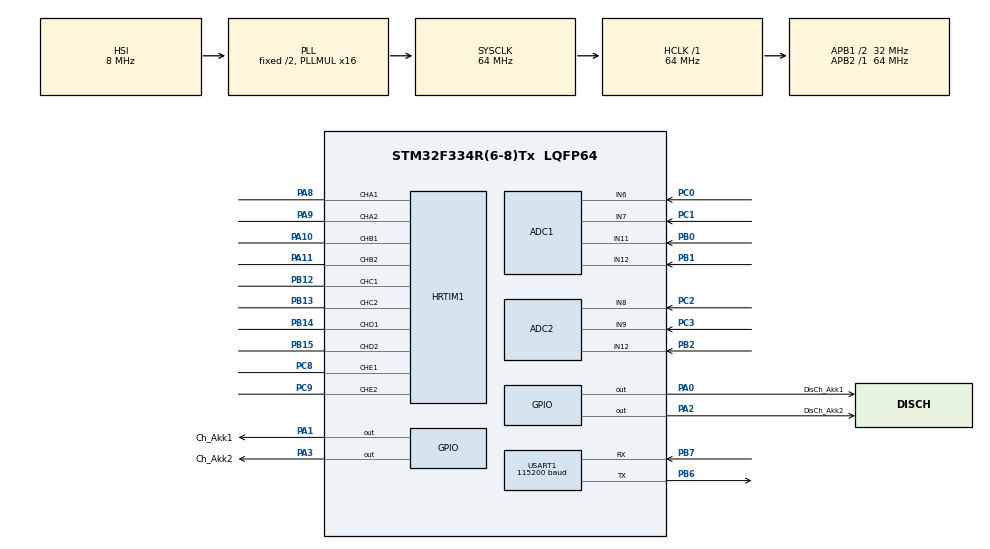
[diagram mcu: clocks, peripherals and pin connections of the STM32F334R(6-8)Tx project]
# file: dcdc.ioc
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ADC1.Channel-0\#ChannelRegularConversion=ADC_CHANNEL_6
ADC1.Channel-1\#ChannelRegularConversion=ADC_CHANNEL_7
ADC1.Channel-2\#ChannelRegularConversion=ADC_CHANNEL_11
ADC1.Channel-3\#ChannelRegularConversion=ADC_CHANNEL_12
ADC1.DMAContinuousRequests=ENABLE
ADC1.DiscontinuousConvMode=ENABLE
ADC1.EOCSelection=ADC_EOC_SINGLE_CONV
ADC1.EnableInjectedConversion=DISABLE
ADC1.ExternalTrigConv=ADC_EXTERNALTRIGCONV_T15_TRGO
ADC1.NbrOfConversion=4
ADC1.NbrOfConversionFlag=1
ADC1.Offset-0\#ChannelRegularConversion=0
ADC1.Offset-1\#ChannelRegularConversion=0
ADC1.Offset-2\#ChannelRegularConversion=0
ADC1.Offset-3\#ChannelRegularConversion=0
ADC1.OffsetNumber-0\#ChannelRegularConversion=ADC_OFFSET_NONE
ADC1.OffsetNumber-1\#ChannelRegularConversion=ADC_OFFSET_NONE
ADC1.OffsetNumber-2\#ChannelRegularConversion=ADC_OFFSET_NONE
ADC1.OffsetNumber-3\#ChannelRegularConversion=ADC_OFFSET_NONE
ADC1.Rank-0\#ChannelRegularConversion=1
ADC1.Rank-1\#ChannelRegularConversion=2
ADC1.Rank-2\#ChannelRegularConversion=3
ADC1.Rank-3\#ChannelRegularConversion=4
ADC1.SamplingTime-0\#ChannelRegularConversion=ADC_SAMPLETIME_1CYCLE_5
ADC1.SamplingTime-1\#ChannelRegularConversion=ADC_SAMPLETIME_1CYCLE_5
ADC1.SamplingTime-2\#ChannelRegularConversion=ADC_SAMPLETIME_1CYCLE_5
ADC1.SamplingTime-3\#ChannelRegularConversion=ADC_SAMPLETIME_1CYCLE_5
ADC1.SamplingTimeOPAMP-1\#ChannelRegularConversion=ADC_SAMPLETIME_61CYCLES_5
ADC1.SamplingTimeOPAMP-2\#ChannelRegularConversion=ADC_SAMPLETIME_61CYCLES_5
ADC1.SamplingTimeOPAMP-3\#ChannelRegularConversion=ADC_SAMPLETIME_61CYCLES_5
ADC1.SubFamily=STM32F334x8
ADC1.master=1
ADC2.Channel-0\#ChannelRegularConversion=ADC_CHANNEL_8
ADC2.Channel-1\#ChannelRegularConversion=ADC_CHANNEL_9
ADC2.Channel-2\#ChannelRegularConversion=ADC_CHANNEL_12
ADC2.DMAContinuousRequests=ENABLE
ADC2.DiscontinuousConvMode=DISABLE
ADC2.EnableInjectedConversion=DISABLE
ADC2.ExternalTrigConv=ADC_EXTERNALTRIGCONV_T15_TRGO
ADC2.NbrOfConversion=3
ADC2.NbrOfConversionFlag=1
ADC2.Offset-0\#ChannelRegularConversion=0
ADC2.Offset-1\#ChannelRegularConversion=0
ADC2.Offset-2\#ChannelRegularConversion=0
ADC2.OffsetNumber-0\#ChannelRegularConversion=ADC_OFFSET_NONE
ADC2.OffsetNumber-1\#ChannelRegularConversion=ADC_OFFSET_NONE
ADC2.OffsetNumber-2\#ChannelRegularConversion=ADC_OFFSET_NONE
ADC2.Rank-0\#ChannelRegularConversion=1
ADC2.Rank-1\#ChannelRegularConversion=2
ADC2.Rank-2\#ChannelRegularConversion=3
ADC2.SamplingTime-0\#ChannelRegularConversion=ADC_SAMPLETIME_61CYCLES_5
ADC2.SamplingTime-1\#ChannelRegularConversion=ADC_SAMPLETIME_61CYCLES_5
ADC2.SamplingTime-2\#ChannelRegularConversion=ADC_SAMPLETIME_61CYCLES_5
ADC2.SamplingTimeOPAMP-1\#ChannelRegularConversion=ADC_SAMPLETIME_61CYCLES_5
ADC2.SamplingTimeOPAMP-2\#ChannelRegularConversion=ADC_SAMPLETIME_61CYCLES_5
ADC2.SubFamily=STM32F334x8
Dma.ADC1.2.Direction=DMA_PERIPH_TO_MEMORY
Dma.ADC1.2.Instance=DMA1_Channel1
Dma.ADC1.2.MemDataAlignment=DMA_MDATAALIGN_HALFWORD
Dma.ADC1.2.MemInc=DMA_MINC_ENABLE
Dma.ADC1.2.Mode=DMA_CIRCULAR
Dma.ADC1.2.PeriphDataAlignment=DMA_PDATAALIGN_HALFWORD
Dma.ADC1.2.PeriphInc=DMA_PINC_DISABLE
Dma.ADC1.2.Priority=DMA_PRIORITY_LOW
Dma.ADC2.3.Direction=DMA_PERIPH_TO_MEMORY
Dma.ADC2.3.Instance=DMA1_Channel2
Dma.ADC2.3.MemDataAlignment=DMA_MDATAALIGN_HALFWORD
Dma.ADC2.3.MemInc=DMA_MINC_ENABLE
Dma.ADC2.3.Mode=DMA_CIRCULAR
Dma.ADC2.3.PeriphDataAlignment=DMA_PDATAALIGN_HALFWORD
Dma.ADC2.3.PeriphInc=DMA_PINC_DISABLE
Dma.ADC2.3.Priority=DMA_PRIORITY_LOW
Dma.Request0=USART1_RX
Dma.Request1=USART1_TX
Dma.Request2=ADC1
Dma.Request3=ADC2
Dma.USART1_RX.0.Direction=DMA_PERIPH_TO_MEMORY
Dma.USART1_RX.0.Instance=DMA1_Channel5
Dma.USART1_RX.0.MemDataAlignment=DMA_MDATAALIGN_BYTE
Dma.USART1_RX.0.MemInc=DMA_MINC_ENABLE
Dma.USART1_RX.0.Mode=DMA_NORMAL
Dma.USART1_RX.0.PeriphDataAlignment=DMA_PDATAALIGN_BYTE
Dma.USART1_RX.0.PeriphInc=DMA_PINC_DISABLE
Dma.USART1_RX.0.Priority=DMA_PRIORITY_LOW
Dma.USART1_TX.1.Direction=DMA_MEMORY_TO_PERIPH
Dma.USART1_TX.1.Instance=DMA1_Channel4
Dma.USART1_TX.1.MemDataAlignment=DMA_MDATAALIGN_BYTE
Dma.USART1_TX.1.MemInc=DMA_MINC_ENABLE
Dma.USART1_TX.1.Mode=DMA_NORMAL
Dma.USART1_TX.1.PeriphDataAlignment=DMA_PDATAALIGN_BYTE
Dma.USART1_TX.1.PeriphInc=DMA_PINC_DISABLE
Dma.USART1_TX.1.Priority=DMA_PRIORITY_LOW
FREERTOS.INCLUDE_xEventGroupSetBitFromISR=1
FREERTOS.INCLUDE_xTimerPendFunctionCall=1
FREERTOS.Queues01=command_queue,100,uint8_t,0,Dynamic,NULL,NULL
FREERTOS.Tasks01=defaultTask,0,128,StartDefaultTask,Default,NULL,Dynamic,NULL,NULL;rx_uart_data,0,128,rx_uart_data_task,As weak,NULL,Dynamic,NULL,NULL;tx_uart_data,0,128,tx_uart_data_task,As weak,NULL,Dynamic,NULL,NULL;charging_akk,2,128,charging_akk_task,As weak,NULL,Dynamic,NULL,NULL
FREERTOS.configLIBRARY_LOWEST_INTERRUPT_PRIORITY=3
FREERTOS.configLIBRARY_MAX_SYSCALL_INTERRUPT_PRIORITY=3
FREERTOS.configUSE_TIMERS=1
HRTIM1.ADCTrigger_Id3=__NULL
HRTIM1.CaptureUnit1-Output_TB1TB2=__NULL
HRTIM1.CompareUnit1-MasterTimer=__NULL
HRTIM1.CompareUnit1-Output_TA1TA2=__NULL
HRTIM1.CompareUnit1-Output_TB1TB2=__NULL
HRTIM1.CompareUnit1-Output_TC1TC2=__NULL
HRTIM1.CompareUnit1-Output_TD1TD2=__NULL
HRTIM1.CompareUnit2-MasterTimer=HRTIM_COMPAREUNIT_2
HRTIM1.CompareUnit2-Output_TA1TA2=__NULL
HRTIM1.CompareUnit2-Output_TB1TB2=__NULL
HRTIM1.CompareUnit2-Output_TC1TC2=__NULL
HRTIM1.CompareUnit2-Output_TD1TD2=__NULL
HRTIM1.CompareUnit3-MasterTimer=HRTIM_COMPAREUNIT_3
HRTIM1.CompareUnit3-Output_TA1TA2=__NULL
HRTIM1.CompareUnit3-Output_TB1TB2=__NULL
HRTIM1.CompareUnit3-Output_TC1TC2=__NULL
HRTIM1.CompareUnit3-Output_TD1TD2=__NULL
HRTIM1.CompareUnit4-MasterTimer=HRTIM_COMPAREUNIT_4
HRTIM1.CompareUnit4-Output_TA1TA2=__NULL
HRTIM1.CompareUnit4-Output_TB1TB2=__NULL
HRTIM1.CompareUnit4-Output_TC1TC2=__NULL
HRTIM1.CompareUnit4-Output_TD1TD2=__NULL
HRTIM1.CompareValue1-MasterTimer=160
HRTIM1.CompareValue1-Output_TA1TA2=3
HRTIM1.CompareValue1-Output_TB1TB2=3
HRTIM1.CompareValue1-Output_TC1TC2=3
HRTIM1.CompareValue1-Output_TD1TD2=3
HRTIM1.CompareValue2-MasterTimer=80
HRTIM1.CompareValue2-Output_TA1TA2=323
HRTIM1.CompareValue2-Output_TB1TB2=323
HRTIM1.CompareValue2-Output_TC1TC2=323
HRTIM1.CompareValue2-Output_TD1TD2=323
HRTIM1.CompareValue3-MasterTimer=160
HRTIM1.CompareValue3-Output_TB1TB2=65533
HRTIM1.CompareValue4-MasterTimer=240
HRTIM1.CompareValue4-Output_TB1TB2=65533
HRTIM1.Configuration_TE=Waveform
HRTIM1.Deadtimeconfig-Output_TB1TB2=__NULL
HRTIM1.Event2-Output_TA1TA2=__NULL
HRTIM1.Event_EEV1=__NULL
HRTIM1.Event_EEV2=__NULL
HRTIM1.Event_EEV5=__NULL
HRTIM1.Event_EEV6=__NULL
HRTIM1.Event_EEV7=__NULL
HRTIM1.Fault_Line1=__NULL
HRTIM1.Fault_Line2=__NULL
HRTIM1.HalfModeEnable-MasterTimer=HRTIM_HALFMODE_DISABLED
HRTIM1.InterruptRequests1_Master=HRTIM_MASTER_IT_NONE
HRTIM1.InterruptRequests2_Master=HRTIM_MASTER_IT_MCMP2
HRTIM1.InterruptRequests3_Master=HRTIM_MASTER_IT_MCMP3
HRTIM1.InterruptRequests4_Master=HRTIM_MASTER_IT_MCMP4
HRTIM1.NumberInterruptRequests-Output_TA1TA2=0
HRTIM1.NumberInterruptRequests_Master-MasterTimer=4
HRTIM1.NumberResetSource1-Output_TA1TA2=1
HRTIM1.NumberResetSource1-Output_TB1TB2=1
HRTIM1.NumberResetSource1-Output_TC1TC2=1
HRTIM1.NumberResetSource1-Output_TD1TD2=1
HRTIM1.NumberResetSource1-Output_TE1TE2=1
HRTIM1.NumberResetSource2_TA=1
HRTIM1.NumberResetSource2_TB=1
HRTIM1.NumberResetSource2_TC=1
HRTIM1.NumberResetSource2_TD=1
HRTIM1.NumberResetTrigger-Output_TA1TA2=0
HRTIM1.NumberSetSource1-Output_TA1TA2=1
HRTIM1.NumberSetSource1-Output_TB1TB2=1
HRTIM1.NumberSetSource1-Output_TC1TC2=1
HRTIM1.NumberSetSource1-Output_TD1TD2=1
HRTIM1.NumberSetSource1-Output_TE1TE2=1
HRTIM1.NumberSetSource2_TA=1
HRTIM1.NumberSetSource2_TB=1
HRTIM1.NumberSetSource2_TC=1
HRTIM1.NumberSetSource2_TD=1
HRTIM1.NumberTriggerSource_Captureconfig1-Output_TB1TB2=0
HRTIM1.OCChannel_TE2=__NULL
HRTIM1.ORingUpdateSource_ADCTrigger3=HRTIM_ADCTRIGGERUPDATE_TIMER_A
HRTIM1.PWMChannel_TE1=__NULL
HRTIM1.Periode_MASTER=320
HRTIM1.Periode_TA=640
HRTIM1.Periode_TB=640
HRTIM1.Periode_TE=640
HRTIM1.Polarity1-Output_TB1TB2=HRTIM_OUTPUTPOLARITY_HIGH
HRTIM1.PrescalerRatio_MASTER=HRTIM_PRESCALERRATIO_DIV1
HRTIM1.ResetOutput1_Source1-Output_TA1TA2=HRTIM_OUTPUTRESET_MASTERCMP4
HRTIM1.ResetOutput1_Source1-Output_TB1TB2=HRTIM_OUTPUTRESET_MASTERCMP2
HRTIM1.ResetOutput1_Source1-Output_TC1TC2=HRTIM_OUTPUTRESET_MASTERCMP4
HRTIM1.ResetOutput1_Source1-Output_TD1TD2=HRTIM_OUTPUTRESET_MASTERCMP4
HRTIM1.ResetOutput1_Source1-Output_TE1TE2=HRTIM_OUTPUTRESET_MASTERCMP2
HRTIM1.ResetOutput2_Source1-Output_TA1TA2=HRTIM_OUTPUTRESET_MASTERCMP2
HRTIM1.ResetOutput2_Source1-Output_TB1TB2=HRTIM_OUTPUTRESET_MASTERCMP4
HRTIM1.ResetOutput2_Source1-Output_TC1TC2=HRTIM_OUTPUTRESET_MASTERCMP2
HRTIM1.ResetOutput2_Source1-Output_TD1TD2=HRTIM_OUTPUTRESET_MASTERCMP2
HRTIM1.SetOutput1_Source1-Output_TA1TA2=HRTIM_OUTPUTSET_MASTERCMP3
HRTIM1.SetOutput1_Source1-Output_TB1TB2=HRTIM_OUTPUTSET_MASTERPER
HRTIM1.SetOutput1_Source1-Output_TC1TC2=HRTIM_OUTPUTSET_MASTERCMP3
HRTIM1.SetOutput1_Source1-Output_TD1TD2=HRTIM_OUTPUTSET_MASTERCMP3
HRTIM1.SetOutput1_Source1-Output_TE1TE2=HRTIM_OUTPUTSET_NONE
HRTIM1.SetOutput2_Source1-Output_TA1TA2=HRTIM_OUTPUTSET_MASTERPER
HRTIM1.SetOutput2_Source1-Output_TB1TB2=HRTIM_OUTPUTSET_MASTERCMP3
HRTIM1.SetOutput2_Source1-Output_TC1TC2=HRTIM_OUTPUTSET_MASTERPER
HRTIM1.SetOutput2_Source1-Output_TD1TD2=HRTIM_OUTPUTSET_MASTERPER
HRTIM1.SyncOptions=HRTIM_SYNCOPTION_NONE
HRTIM1.TriggerCapture1_Source1-Output_TB1TB2=HRTIM_CAPTURETRIGGER_TIMERB_CMP1
Mcu.Family=STM32F3
Mcu.Name=STM32F334R(6-8)Tx
Mcu.Package=LQFP64
NVIC.ADC1_2_IRQn=true\:3\:0\:true\:false\:true\:false\:true\:true
NVIC.DMA1_Channel1_IRQn=true\:3\:0\:false\:false\:true\:true\:false\:true
NVIC.DMA1_Channel2_IRQn=true\:3\:0\:false\:false\:true\:true\:false\:true
NVIC.DMA1_Channel4_IRQn=true\:3\:0\:false\:false\:true\:true\:false\:true
NVIC.DMA1_Channel5_IRQn=true\:3\:0\:false\:false\:true\:true\:false\:true
NVIC.PriorityGroup=NVIC_PRIORITYGROUP_4
NVIC.TIM1_UP_TIM16_IRQn=true\:0\:0\:false\:false\:true\:false\:false\:true
NVIC.TimeBase=TIM1_UP_TIM16_IRQn
NVIC.TimeBaseIP=TIM1
NVIC.USART1_IRQn=true\:5\:0\:true\:false\:true\:true\:true\:true
PA0.GPIO_Label=DisCh_Akk1
PA0.Signal=GPIO_Output
PA1.GPIO_Label=Ch_Akk1
PA1.Signal=GPIO_Output
PA10.Mode=Output_TB1TB2
PA10.Signal=HRTIM1_CHB1
PA11.Mode=Output_TB1TB2
PA11.Signal=HRTIM1_CHB2
PA13.GPIO_Label=TMS
PA13.Mode=Serial_Wire
PA13.Signal=SYS_JTMS-SWDIO
PA14.GPIO_Label=TCK
PA14.Mode=Serial_Wire
PA14.Signal=SYS_JTCK-SWCLK
PA2.GPIO_Label=DisCh_Akk2
PA2.Signal=GPIO_Output
PA3.GPIO_Label=Ch_Akk2
PA3.Signal=GPIO_Output
PA8.Mode=Output_TA1TA2
PA8.Signal=HRTIM1_CHA1
PA9.Mode=Output_TA1TA2
PA9.Signal=HRTIM1_CHA2
PB0.Mode=IN11-Single-Ended
PB0.Signal=ADC1_IN11
PB1.Mode=IN12-Single-Ended
PB1.Signal=ADC1_IN12
PB12.Mode=Output_TC1TC2
PB12.Signal=HRTIM1_CHC1
PB13.Mode=Output_TC1TC2
PB13.Signal=HRTIM1_CHC2
PB14.Mode=Output_TD1TD2
PB14.Signal=HRTIM1_CHD1
PB15.Mode=Output_TD1TD2
PB15.Signal=HRTIM1_CHD2
PB2.Mode=IN12-Single-Ended
PB2.Signal=ADC2_IN12
PB3.GPIO_Label=SWO
PB3.Signal=SYS_JTDO-TRACESWO
PB6.Mode=Asynchronous
PB6.Signal=USART1_TX
PB7.Mode=Asynchronous
PB7.Signal=USART1_RX
PC0.Signal=ADCx_IN6
PC1.Signal=ADCx_IN7
PC14\ /\ OSC32_IN.Mode=LSE-External-Oscillator
PC14\ /\ OSC32_IN.Signal=RCC_OSC32_IN
PC15\ /\ OSC32_OUT.GPIO_Label=RCC_OSC32_OUT
PC15\ /\ OSC32_OUT.Mode=LSE-External-Oscillator
PC15\ /\ OSC32_OUT.Signal=RCC_OSC32_OUT
PC2.Signal=ADCx_IN8
PC3.Signal=ADCx_IN9
PC8.Mode=Output_TE1TE2
PC8.Signal=HRTIM1_CHE1
PC9.Mode=Output_TE1TE2
PC9.Signal=HRTIM1_CHE2
PF0\ /\ OSC_IN.Mode=HSE-External-Clock-Source
PF0\ /\ OSC_IN.Signal=RCC_OSC_IN
PF1\ /\ OSC_OUT.Signal=RCC_OSC_OUT
ProjectManager.HeapSize=0x200
ProjectManager.StackSize=0x400
ProjectManager.TargetToolchain=STM32CubeIDE
RCC.AHBFreq_Value=64000000
RCC.APB1CLKDivider=RCC_HCLK_DIV2
RCC.APB1Freq_Value=32000000
RCC.APB1TimFreq_Value=64000000
RCC.APB2Freq_Value=64000000
RCC.APB2TimFreq_Value=64000000
RCC.CortexFreq_Value=64000000
RCC.FLatency-AdvancedSettings=FLASH_LATENCY_2
RCC.HCLKFreq_Value=64000000
RCC.HSE_VALUE=8000000
RCC.HSI_VALUE=8000000
RCC.PLLMUL=RCC_PLL_MUL16
RCC.SYSCLKFreq_VALUE=64000000
RCC.SYSCLKSourceVirtual=RCC_SYSCLKSOURCE_PLLCLK
SH.ADCx_IN6.0=ADC1_IN6,IN6-Single-Ended
SH.ADCx_IN7.0=ADC1_IN7,IN7-Single-Ended
SH.ADCx_IN8.0=ADC2_IN8,IN8-Single-Ended
SH.ADCx_IN9.0=ADC2_IN9,IN9-Single-Ended
TIM15.Period=100
TIM15.Prescaler=32000
TIM15.TIM_MasterOutputTrigger=TIM_TRGO_UPDATE
USART1.BaudRate=115200
USART1.SwapParam=ADVFEATURE_SWAP_DISABLE
USART1.VirtualMode-Asynchronous=VM_ASYNC
VP_FREERTOS_VS_CMSIS_V1.Mode=CMSIS_V1
VP_HRTIM1_VS_hrtimMasterTimerNoOutput.Mode=MasterTimer
VP_SYS_VS_tim1.Mode=TIM1
VP_TIM15_VS_ClockSourceINT.Mode=Internal
board=NUCLEO-F334R8

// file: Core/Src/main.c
/* USER CODE BEGIN Header */
/**
  ******************************************************************************
  * @file           : main.c
  * @brief          : Main program body
  ******************************************************************************
  * @attention
  *
  * <h2><center>&copy; Copyright (c) 2020 STMicroelectronics.
  * All rights reserved.</center></h2>
  *
  * This software component is licensed by ST under Ultimate Liberty license
  * SLA0044, the "License"; You may not use this file except in compliance with
  * the License. You may obtain a copy of the License at:
  *                             www.st.com/SLA0044
  *
  ******************************************************************************
  */
/* USER CODE END Header */
#include "main.h"
#include "cmsis_os.h"
#include "adc.h"
#include "dma.h"
#include "hrtim.h"
#include "tim.h"
#include "usart.h"
#include "gpio.h"

/* USER CODE BEGIN Includes */
#include "uart_data_transfer_core.h"
#include "charger_core.h"
/* USER CODE END Includes */

void SystemClock_Config(void);
void MX_FREERTOS_Init(void);

/* USER CODE BEGIN 0 */
// FOR PARSER INIT:
#include "smart_ups_data_base.h"
#include "user_comand.h"
#include "parser.h"
/* USER CODE END 0 */

int main(void)
{

  /* MCU Configuration--------------------------------------------------------*/

  /* Reset of all peripherals, Initializes the Flash interface and the Systick. */
  HAL_Init();

  /* Configure the system clock */
  SystemClock_Config();

  /* Initialize all configured peripherals */
  MX_GPIO_Init();
  MX_DMA_Init();
  MX_USART1_UART_Init();
  MX_HRTIM1_Init();
  MX_ADC1_Init();
  MX_ADC2_Init();
  MX_TIM15_Init();
  /* USER CODE BEGIN 2 */

  parser_create(&groups_of_commands, MAX_CMD_LEN);
  init_uart_data_transfer();
  charger_init();
  start_measurements();
  /* USER CODE END 2 */

  /* Call init function for freertos objects (in freertos.c) */
  MX_FREERTOS_Init();
  /* Start scheduler */
  osKernelStart();

  /* We should never get here as control is now taken by the scheduler */
  /* Infinite loop */
  while (1)
  {

  }
}

void SystemClock_Config(void)
{
  RCC_OscInitTypeDef RCC_OscInitStruct = {0};
  RCC_ClkInitTypeDef RCC_ClkInitStruct = {0};
  RCC_PeriphCLKInitTypeDef PeriphClkInit = {0};

  /** Initializes the RCC Oscillators according to the specified parameters
  * in the RCC_OscInitTypeDef structure.
  */
  RCC_OscInitStruct.OscillatorType = RCC_OSCILLATORTYPE_HSI;
  RCC_OscInitStruct.HSIState = RCC_HSI_ON;
  RCC_OscInitStruct.HSICalibrationValue = RCC_HSICALIBRATION_DEFAULT;
  RCC_OscInitStruct.PLL.PLLState = RCC_PLL_ON;
  RCC_OscInitStruct.PLL.PLLSource = RCC_PLLSOURCE_HSI;
  RCC_OscInitStruct.PLL.PLLMUL = RCC_PLL_MUL16;
  if (HAL_RCC_OscConfig(&RCC_OscInitStruct) != HAL_OK)
  {
    Error_Handler();
  }
  /** Initializes the CPU, AHB and APB buses clocks
  */
  RCC_ClkInitStruct.ClockType = RCC_CLOCKTYPE_HCLK|RCC_CLOCKTYPE_SYSCLK
                              |RCC_CLOCKTYPE_PCLK1|RCC_CLOCKTYPE_PCLK2;
  RCC_ClkInitStruct.SYSCLKSource = RCC_SYSCLKSOURCE_PLLCLK;
  RCC_ClkInitStruct.AHBCLKDivider = RCC_SYSCLK_DIV1;
  RCC_ClkInitStruct.APB1CLKDivider = RCC_HCLK_DIV2;
  RCC_ClkInitStruct.APB2CLKDivider = RCC_HCLK_DIV1;

  if (HAL_RCC_ClockConfig(&RCC_ClkInitStruct, FLASH_LATENCY_2) != HAL_OK)
  {
    Error_Handler();
  }
  PeriphClkInit.PeriphClockSelection = RCC_PERIPHCLK_HRTIM1|RCC_PERIPHCLK_USART1
                              |RCC_PERIPHCLK_ADC12;
  PeriphClkInit.Usart1ClockSelection = RCC_USART1CLKSOURCE_PCLK1;
  PeriphClkInit.Adc12ClockSelection = RCC_ADC12PLLCLK_DIV1;
  PeriphClkInit.Hrtim1ClockSelection = RCC_HRTIM1CLK_HCLK;
  if (HAL_RCCEx_PeriphCLKConfig(&PeriphClkInit) != HAL_OK)
  {
    Error_Handler();
  }
}

void HAL_TIM_PeriodElapsedCallback(TIM_HandleTypeDef *htim)
{
  if (htim->Instance == TIM1) {
    HAL_IncTick();
  }
}

void Error_Handler(void)
{
}

/************************ (C) COPYRIGHT STMicroelectronics *****END OF FILE****/

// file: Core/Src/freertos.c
/* USER CODE BEGIN Header */
/**
  ******************************************************************************
  * File Name          : freertos.c
  * Description        : Code for freertos applications
  ******************************************************************************
  * @attention
  *
  * <h2><center>&copy; Copyright (c) 2020 STMicroelectronics.
  * All rights reserved.</center></h2>
  *
  * This software component is licensed by ST under Ultimate Liberty license
  * SLA0044, the "License"; You may not use this file except in compliance with
  * the License. You may obtain a copy of the License at:
  *                             www.st.com/SLA0044
  *
  ******************************************************************************
  */
/* USER CODE END Header */

#include "FreeRTOS.h"
#include "task.h"
#include "main.h"
#include "cmsis_os.h"

osThreadId defaultTaskHandle;
osThreadId rx_uart_dataHandle;
osThreadId tx_uart_dataHandle;
osThreadId charging_akkHandle;
osMessageQId command_queueHandle;

void StartDefaultTask(void const * argument);
void rx_uart_data_task(void const * argument);
void tx_uart_data_task(void const * argument);
void charging_akk_task(void const * argument);

void MX_FREERTOS_Init(void); /* (MISRA C 2004 rule 8.1) */

/* GetIdleTaskMemory prototype (linked to static allocation support) */
void vApplicationGetIdleTaskMemory( StaticTask_t **ppxIdleTaskTCBBuffer, StackType_t **ppxIdleTaskStackBuffer, uint32_t *pulIdleTaskStackSize );

/* GetTimerTaskMemory prototype (linked to static allocation support) */
void vApplicationGetTimerTaskMemory( StaticTask_t **ppxTimerTaskTCBBuffer, StackType_t **ppxTimerTaskStackBuffer, uint32_t *pulTimerTaskStackSize );

/* USER CODE BEGIN GET_IDLE_TASK_MEMORY */
static StaticTask_t xIdleTaskTCBBuffer;
static StackType_t xIdleStack[configMINIMAL_STACK_SIZE];

void vApplicationGetIdleTaskMemory( StaticTask_t **ppxIdleTaskTCBBuffer, StackType_t **ppxIdleTaskStackBuffer, uint32_t *pulIdleTaskStackSize )
{
  *ppxIdleTaskTCBBuffer = &xIdleTaskTCBBuffer;
  *ppxIdleTaskStackBuffer = &xIdleStack[0];
  *pulIdleTaskStackSize = configMINIMAL_STACK_SIZE;
  /* place for user code */
}
/* USER CODE END GET_IDLE_TASK_MEMORY */

/* USER CODE BEGIN GET_TIMER_TASK_MEMORY */
static StaticTask_t xTimerTaskTCBBuffer;
static StackType_t xTimerStack[configTIMER_TASK_STACK_DEPTH];

void vApplicationGetTimerTaskMemory( StaticTask_t **ppxTimerTaskTCBBuffer, StackType_t **ppxTimerTaskStackBuffer, uint32_t *pulTimerTaskStackSize )
{
  *ppxTimerTaskTCBBuffer = &xTimerTaskTCBBuffer;
  *ppxTimerTaskStackBuffer = &xTimerStack[0];
  *pulTimerTaskStackSize = configTIMER_TASK_STACK_DEPTH;
  /* place for user code */
}
/* USER CODE END GET_TIMER_TASK_MEMORY */

void MX_FREERTOS_Init(void) {

  /* Create the queue(s) */
  /* definition and creation of command_queue */
  osMessageQDef(command_queue, 100, uint8_t);
  command_queueHandle = osMessageCreate(osMessageQ(command_queue), NULL);

  /* Create the thread(s) */
  /* definition and creation of defaultTask */
  osThreadDef(defaultTask, StartDefaultTask, osPriorityNormal, 0, 128);
  defaultTaskHandle = osThreadCreate(osThread(defaultTask), NULL);

  /* definition and creation of rx_uart_data */
  osThreadDef(rx_uart_data, rx_uart_data_task, osPriorityNormal, 0, 128);
  rx_uart_dataHandle = osThreadCreate(osThread(rx_uart_data), NULL);

  /* definition and creation of tx_uart_data */
  osThreadDef(tx_uart_data, tx_uart_data_task, osPriorityNormal, 0, 128);
  tx_uart_dataHandle = osThreadCreate(osThread(tx_uart_data), NULL);

  /* definition and creation of charging_akk */
  osThreadDef(charging_akk, charging_akk_task, osPriorityHigh, 0, 128);
  charging_akkHandle = osThreadCreate(osThread(charging_akk), NULL);

}

/* USER CODE BEGIN Header_StartDefaultTask */
/**
  * @brief  Function implementing the defaultTask thread.
  * @param  argument: Not used
  * @retval None
  */
#include "usart.h"
#include "../../../software/inc/parser/parser.h"

/* USER CODE END Header_StartDefaultTask */
void StartDefaultTask(void const * argument)
{
	for(;;)
	{
		osDelay(1);
	}
}

__weak void rx_uart_data_task(void const * argument)
{
  for(;;)
  {
    osDelay(1);
  }
}

__weak void tx_uart_data_task(void const * argument)
{
  for(;;)
  {
    osDelay(1);
  }
}

__weak void charging_akk_task(void const * argument)
{
  for(;;)
  {
    osDelay(1);
  }
}

/************************ (C) COPYRIGHT STMicroelectronics *****END OF FILE****/
